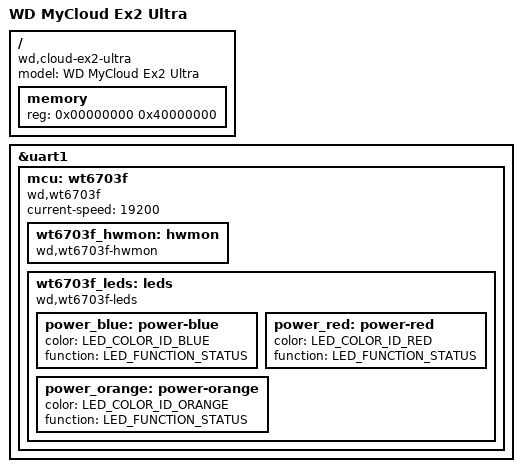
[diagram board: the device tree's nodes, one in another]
// SPDX-License-Identifier: (GPL-2.0+ OR MIT)
/dts-v1/;
#include "armada-385-wd_cloud.dtsi"

/ {
	model = "WD MyCloud Ex2 Ultra";
	compatible = "wd,cloud-ex2-ultra", "marvell,armada385", "marvell,armada380";

	memory {
		device_type = "memory";
		reg = <0x00000000 0x40000000>; /* 1GB */
	};
};

/*
 * WT6703F MCU
 */
&uart1 {
	status = "okay";

	mcu: wt6703f {
		compatible = "wd,wt6703f";
		current-speed = <19200>;

		wt6703f_hwmon: hwmon {
			compatible = "wd,wt6703f-hwmon";
		};

		wt6703f_leds: leds {
			compatible = "wd,wt6703f-leds";

			power_blue: power-blue {
				color = <LED_COLOR_ID_BLUE>;
				function = LED_FUNCTION_STATUS;
			};

			power_red: power-red {
				color = <LED_COLOR_ID_RED>;
				function = LED_FUNCTION_STATUS;
			};

			power_orange: power-orange {
				color = <LED_COLOR_ID_ORANGE>;
				function = LED_FUNCTION_STATUS;
			};
		};
	};
};
